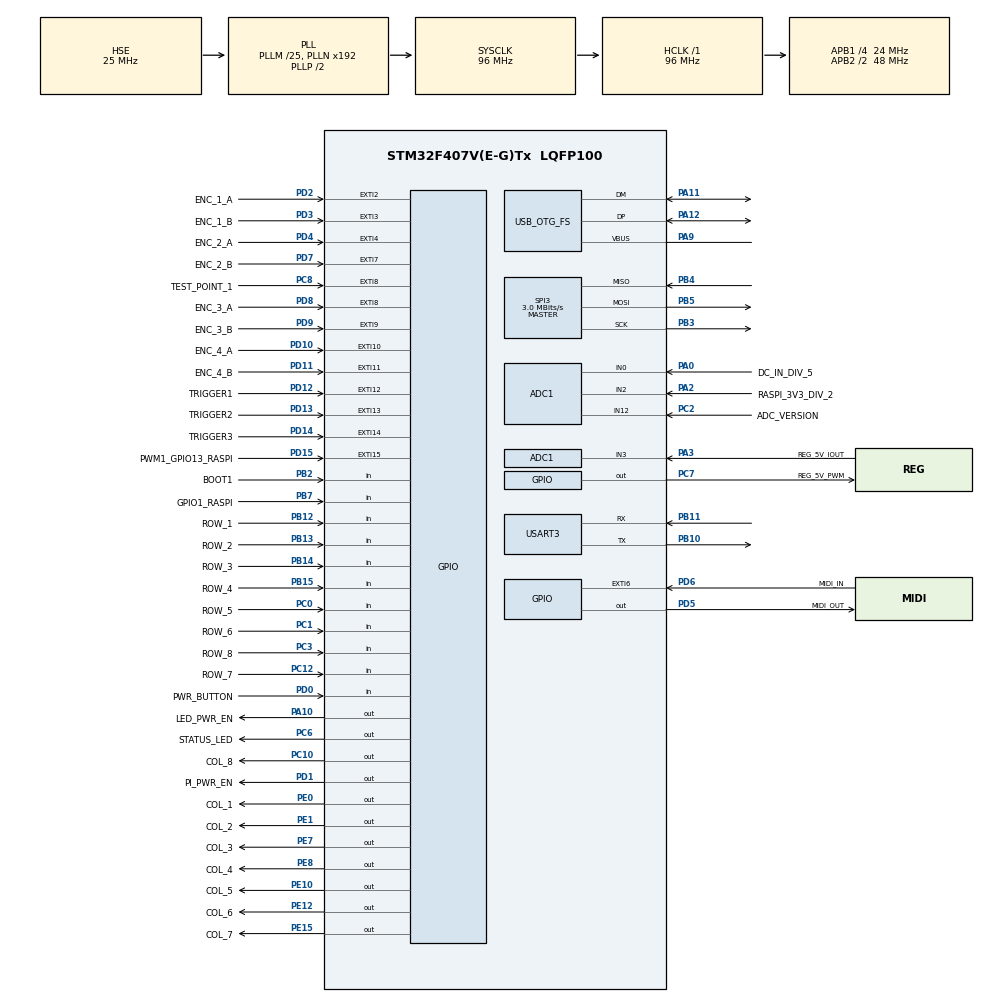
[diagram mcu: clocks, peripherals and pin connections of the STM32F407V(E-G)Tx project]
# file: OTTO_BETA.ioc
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ADC1.Channel-0\#ChannelRegularConversion=ADC_CHANNEL_3
ADC1.NbrOfConversionFlag=1
ADC1.Rank-0\#ChannelRegularConversion=1
ADC1.SamplingTime-0\#ChannelRegularConversion=ADC_SAMPLETIME_3CYCLES
ADC1.master=1
Dma.Request0=SPI3_TX
Dma.SPI3_TX.0.Direction=DMA_MEMORY_TO_PERIPH
Dma.SPI3_TX.0.FIFOMode=DMA_FIFOMODE_DISABLE
Dma.SPI3_TX.0.Instance=DMA1_Stream5
Dma.SPI3_TX.0.MemDataAlignment=DMA_MDATAALIGN_BYTE
Dma.SPI3_TX.0.MemInc=DMA_MINC_ENABLE
Dma.SPI3_TX.0.Mode=DMA_NORMAL
Dma.SPI3_TX.0.PeriphDataAlignment=DMA_PDATAALIGN_BYTE
Dma.SPI3_TX.0.PeriphInc=DMA_PINC_DISABLE
Dma.SPI3_TX.0.Priority=DMA_PRIORITY_LOW
Mcu.Family=STM32F4
Mcu.Name=STM32F407V(E-G)Tx
Mcu.Package=LQFP100
NVIC.DMA1_Stream5_IRQn=true\:0\:0\:false\:false\:true\:false\:true
NVIC.EXTI15_10_IRQn=true\:0\:0\:false\:false\:true\:true\:true
NVIC.EXTI2_IRQn=true\:0\:0\:false\:false\:true\:true\:true
NVIC.EXTI3_IRQn=true\:0\:0\:false\:false\:true\:true\:true
NVIC.EXTI4_IRQn=true\:0\:0\:false\:false\:true\:true\:true
NVIC.EXTI9_5_IRQn=true\:0\:0\:false\:false\:true\:true\:true
NVIC.PriorityGroup=NVIC_PRIORITYGROUP_4
PA0-WKUP.GPIO_Label=DC_IN_DIV_5
PA0-WKUP.Signal=ADCx_IN0
PA10.GPIO_Label=LED_PWR_EN
PA10.Signal=GPIO_Output
PA11.Mode=Device_Only
PA11.Signal=USB_OTG_FS_DM
PA12.Mode=Device_Only
PA12.Signal=USB_OTG_FS_DP
PA13.Mode=Serial_Wire
PA13.Signal=SYS_JTMS-SWDIO
PA14.Mode=Serial_Wire
PA14.Signal=SYS_JTCK-SWCLK
PA2.GPIO_Label=RASPI_3V3_DIV_2
PA2.Signal=ADCx_IN2
PA3.GPIO_Label=REG_5V_IOUT
PA3.Signal=ADCx_IN3
PA9.Mode=Activate_VBUS
PA9.Signal=USB_OTG_FS_VBUS
PB10.Mode=Asynchronous
PB10.Signal=USART3_TX
PB11.Mode=Asynchronous
PB11.Signal=USART3_RX
PB12.GPIO_Label=ROW_1
PB12.Signal=GPIO_Input
PB13.GPIO_Label=ROW_2
PB13.Signal=GPIO_Input
PB14.GPIO_Label=ROW_3
PB14.Signal=GPIO_Input
PB15.GPIO_Label=ROW_4
PB15.Signal=GPIO_Input
PB2.GPIO_Label=BOOT1
PB2.Signal=GPIO_Input
PB3.Mode=Full_Duplex_Master
PB3.Signal=SPI3_SCK
PB4.Mode=Full_Duplex_Master
PB4.Signal=SPI3_MISO
PB5.Mode=Full_Duplex_Master
PB5.Signal=SPI3_MOSI
PB7.GPIO_Label=GPIO1_RASPI
PB7.Signal=GPIO_Input
PB8.Signal=I2C1_SCL
PB9.Signal=I2C1_SDA
PC0.GPIO_Label=ROW_5
PC0.Signal=GPIO_Input
PC1.GPIO_Label=ROW_6
PC1.Signal=GPIO_Input
PC10.GPIO_Label=COL_8
PC10.Signal=GPIO_Output
PC12.GPIO_Label=ROW_7
PC12.Signal=GPIO_Input
PC14-OSC32_IN.Mode=LSE-External-Oscillator
PC14-OSC32_IN.Signal=RCC_OSC32_IN
PC15-OSC32_OUT.Mode=LSE-External-Oscillator
PC15-OSC32_OUT.Signal=RCC_OSC32_OUT
PC2.GPIO_Label=ADC_VERSION
PC2.Signal=ADCx_IN12
PC3.GPIO_Label=ROW_8
PC3.Signal=GPIO_Input
PC6.GPIO_Label=STATUS_LED
PC6.Signal=GPIO_Output
PC7.GPIO_Label=REG_5V_PWM
PC7.Signal=GPIO_Output
PC8.GPIO_Label=TEST_POINT_1
PC8.Signal=GPXTI8
PD0.GPIO_Label=PWR_BUTTON
PD0.Signal=GPIO_Input
PD1.GPIO_Label=PI_PWR_EN
PD1.Signal=GPIO_Output
PD10.GPIO_Label=ENC_4_A
PD10.Signal=GPXTI10
PD11.GPIO_Label=ENC_4_B
PD11.Signal=GPXTI11
PD12.GPIO_Label=TRIGGER1
PD12.Signal=GPXTI12
PD13.GPIO_Label=TRIGGER2
PD13.Signal=GPXTI13
PD14.GPIO_Label=TRIGGER3
PD14.Signal=GPXTI14
PD15.GPIO_Label=PWM1_GPIO13_RASPI
PD15.Signal=GPXTI15
PD2.GPIO_Label=ENC_1_A
PD2.GPIO_ModeDefaultEXTI=GPIO_MODE_IT_RISING_FALLING
PD2.Signal=GPXTI2
PD3.GPIO_Label=ENC_1_B
PD3.Signal=GPXTI3
PD4.GPIO_Label=ENC_2_A
PD4.Signal=GPXTI4
PD5.GPIO_Label=MIDI_OUT
PD5.Signal=GPIO_Output
PD6.GPIO_Label=MIDI_IN
PD6.Signal=GPXTI6
PD7.GPIO_Label=ENC_2_B
PD7.Signal=GPXTI7
PD8.GPIO_Label=ENC_3_A
PD8.Signal=GPXTI8
PD9.GPIO_Label=ENC_3_B
PD9.Signal=GPXTI9
PE0.GPIO_Label=COL_1
PE0.Signal=GPIO_Output
PE1.GPIO_Label=COL_2
PE1.Signal=GPIO_Output
PE10.GPIO_Label=COL_5
PE10.Signal=GPIO_Output
PE12.GPIO_Label=COL_6
PE12.Signal=GPIO_Output
PE15.GPIO_Label=COL_7
PE15.Signal=GPIO_Output
PE7.GPIO_Label=COL_3
PE7.Signal=GPIO_Output
PE8.GPIO_Label=COL_4
PE8.Signal=GPIO_Output
PH0-OSC_IN.Mode=HSE-External-Oscillator
PH0-OSC_IN.Signal=RCC_OSC_IN
PH1-OSC_OUT.Mode=HSE-External-Oscillator
PH1-OSC_OUT.Signal=RCC_OSC_OUT
ProjectManager.HeapSize=0x200
ProjectManager.StackSize=0x400
ProjectManager.TargetToolchain=Makefile
RCC.48MHZClocksFreq_Value=48000000
RCC.AHBFreq_Value=96000000
RCC.APB1CLKDivider=RCC_HCLK_DIV4
RCC.APB1Freq_Value=24000000
RCC.APB1TimFreq_Value=48000000
RCC.APB2CLKDivider=RCC_HCLK_DIV2
RCC.APB2Freq_Value=48000000
RCC.APB2TimFreq_Value=96000000
RCC.CortexFreq_Value=96000000
RCC.HCLKFreq_Value=96000000
RCC.HSE_VALUE=25000000
RCC.HSI_VALUE=16000000
RCC.PLLM=25
RCC.SYSCLKFreq_VALUE=96000000
RCC.SYSCLKSource=RCC_SYSCLKSOURCE_PLLCLK
RCC.VCOOutputFreq_Value=192000000
SH.ADCx_IN0.0=ADC1_IN0,IN0
SH.ADCx_IN12.0=ADC1_IN12,IN12
SH.ADCx_IN2.0=ADC1_IN2,IN2
SH.ADCx_IN3.0=ADC1_IN3,IN3
SPI3.BaudRatePrescaler=SPI_BAUDRATEPRESCALER_8
SPI3.CalculateBaudRate=3.0 MBits/s
SPI3.Direction=SPI_DIRECTION_2LINES
SPI3.Mode=SPI_MODE_MASTER
SPI3.VirtualType=VM_MASTER
USART3.VirtualMode=VM_ASYNC
USB_OTG_FS.VirtualMode=Device_Only
board=custom

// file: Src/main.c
/* USER CODE BEGIN Header */
/**
 ******************************************************************************
 * @file           : main.c
 * @brief          : Main program body
 ******************************************************************************
 * @attention
 *
 * <h2><center>&copy; Copyright (c) 2020 STMicroelectronics.
 * All rights reserved.</center></h2>
 *
 * This software component is licensed by ST under BSD 3-Clause license,
 * the "License"; You may not use this file except in compliance with the
 * License. You may obtain a copy of the License at:
 *                        opensource.org/licenses/BSD-3-Clause
 *
 ******************************************************************************
 */
/* USER CODE END Header */
#include "main.h"
#include "adc.h"
#include "dma.h"
#include "spi.h"
#include "usart.h"
#include "usb_otg.h"
#include "gpio.h"

/* USER CODE BEGIN Includes */
#include "../Cpp/otto.h"
/* USER CODE END Includes */

void SystemClock_Config(void);

int main(void)
{

  /* MCU Configuration--------------------------------------------------------*/

  /* Reset of all peripherals, Initializes the Flash interface and the Systick. */
  HAL_Init();

  /* Configure the system clock */
  SystemClock_Config();

  /* USER CODE BEGIN SysInit */
  OTTO_preinit();
  /* USER CODE END SysInit */

  /* Initialize all configured peripherals */
  MX_GPIO_Init();
  MX_DMA_Init();
  MX_USB_OTG_FS_PCD_Init();
  MX_ADC1_Init();
  MX_SPI3_Init();
  MX_USART3_UART_Init();

  /* Infinite loop */
  /* USER CODE BEGIN WHILE */
  OTTO_main_loop();
    /* USER CODE END WHILE */

}

void SystemClock_Config(void)
{
  RCC_OscInitTypeDef RCC_OscInitStruct = {0};
  RCC_ClkInitTypeDef RCC_ClkInitStruct = {0};

  /** Configure the main internal regulator output voltage
  */
  __HAL_RCC_PWR_CLK_ENABLE();
  __HAL_PWR_VOLTAGESCALING_CONFIG(PWR_REGULATOR_VOLTAGE_SCALE1);
  /** Initializes the RCC Oscillators according to the specified parameters
  * in the RCC_OscInitTypeDef structure.
  */
  RCC_OscInitStruct.OscillatorType = RCC_OSCILLATORTYPE_HSE;
  RCC_OscInitStruct.HSEState = RCC_HSE_ON;
  RCC_OscInitStruct.PLL.PLLState = RCC_PLL_ON;
  RCC_OscInitStruct.PLL.PLLSource = RCC_PLLSOURCE_HSE;
  RCC_OscInitStruct.PLL.PLLM = 25;
  RCC_OscInitStruct.PLL.PLLN = 192;
  RCC_OscInitStruct.PLL.PLLP = RCC_PLLP_DIV2;
  RCC_OscInitStruct.PLL.PLLQ = 4;
  if (HAL_RCC_OscConfig(&RCC_OscInitStruct) != HAL_OK)
  {
    Error_Handler();
  }
  /** Initializes the CPU, AHB and APB buses clocks
  */
  RCC_ClkInitStruct.ClockType = RCC_CLOCKTYPE_HCLK|RCC_CLOCKTYPE_SYSCLK
                              |RCC_CLOCKTYPE_PCLK1|RCC_CLOCKTYPE_PCLK2;
  RCC_ClkInitStruct.SYSCLKSource = RCC_SYSCLKSOURCE_PLLCLK;
  RCC_ClkInitStruct.AHBCLKDivider = RCC_SYSCLK_DIV1;
  RCC_ClkInitStruct.APB1CLKDivider = RCC_HCLK_DIV4;
  RCC_ClkInitStruct.APB2CLKDivider = RCC_HCLK_DIV2;

  if (HAL_RCC_ClockConfig(&RCC_ClkInitStruct, FLASH_LATENCY_3) != HAL_OK)
  {
    Error_Handler();
  }
}

void Error_Handler(void)
{
}

#ifdef  USE_FULL_ASSERT
/**
  * @brief  Reports the name of the source file and the source line number
  *         where the assert_param error has occurred.
  * @param  file: pointer to the source file name
  * @param  line: assert_param error line source number
  * @retval None
  */
void assert_failed(uint8_t *file, uint32_t line)
{
  /* USER CODE BEGIN 6 */
  /* User can add his own implementation to report the file name and line
     number,
     tex: printf("Wrong parameters value: file %s on line %d\r\n", file, line)
   */
  /* USER CODE END 6 */
}
#endif /* USE_FULL_ASSERT */

/************************ (C) COPYRIGHT STMicroelectronics *****END OF FILE****/
